# MM32SPINxxxx register map
Vendor: MindMotion Ltd.; Series: MM32SPIN; File version: 1.4
CPU: CM0 r0p0, little endian, no MPU, no FPU, 3 interrupt priority bits
Registers are 32-bit, read-write, reset 0x0 unless marked. A register's access mark holds for its fields unless they carry their own. Offsets are from the block's base; [hi:lo] are bit positions.

## WWDG — Window watchdog
Base 0x40002C00
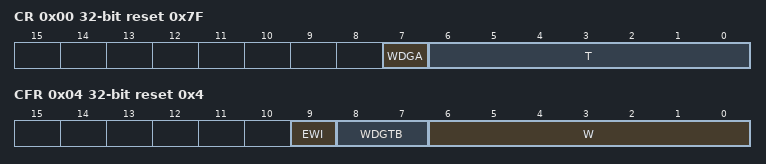
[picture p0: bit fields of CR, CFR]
0x00 CR reset 0x7F
  [7] WDGA — Activation bit
  [6:0] T — 7-bit counter
0x04 CFR reset 0x4
  [9] EWI — Early wakeup interrupt
  [8:7] WDGTB — Timer base
  [6:0] W — 7-bit window value
0x08 SR
  [0] EWIF — Early wakeup interrupt flag

## IWDG — Independent watchdog
Base 0x40003000
0x00 KR wo
  [15:0] KEY — Key value
0x04 PR
  [2:0] PR — Prescaler divider
0x08 RLR
  [11:0] RL — Watchdog counter reload value
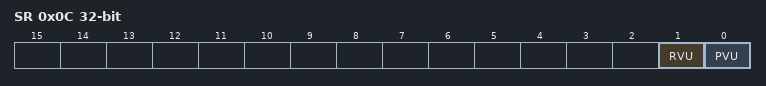
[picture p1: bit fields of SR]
0x0C SR ro
  [1] RVU — Watchdog counter reload value update
  [0] PVU — Watchdog prescaler value update

## TIM14 — Advanced timer
Base 0x40014000
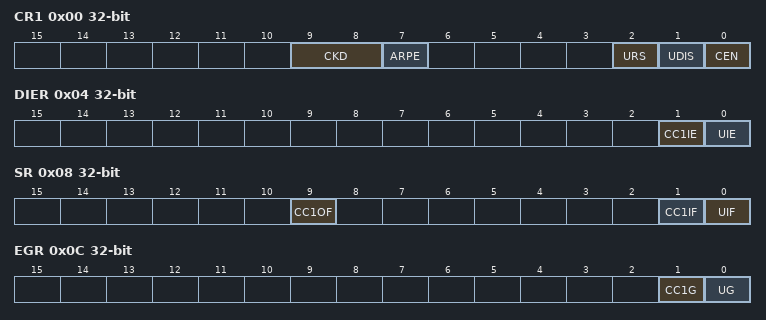
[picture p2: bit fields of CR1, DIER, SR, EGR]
0x00 CR1
  [9:8] CKD, [7] ARPE, [2] URS, [1] UDIS, [0] CEN
0x04 DIER
  [1] CC1IE, [0] UIE
0x08 SR
  [9] CC1OF, [1] CC1IF, [0] UIF
0x0C EGR wo
  [1] CC1G, [0] UG
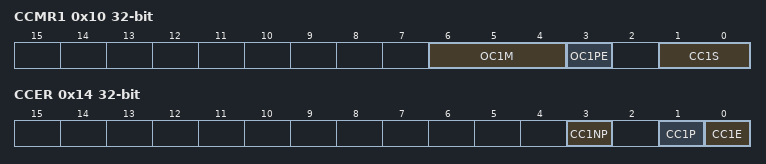
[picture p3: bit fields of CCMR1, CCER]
0x10 CCMR1
  [6:4] OC1M, [3] OC1PE, [1:0] CC1S
0x14 CCER
  [3] CC1NP, [1] CC1P, [0] CC1E
0x18 CNT
  [15:0] CNT
0x1C PSC
  [15:0] PSE
0x20 ARR
  [15:0] ARR
0x24 CRR1
  [15:0] CRR1

## TIM16 — Advanced timer
Base 0x40014400
Same registers: TIM17 0x40014800
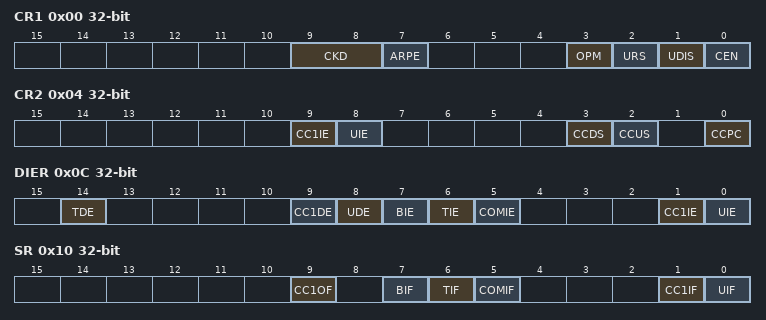
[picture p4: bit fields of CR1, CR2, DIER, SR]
0x00 CR1
  [9:8] CKD, [7] ARPE, [3] OPM, [2] URS, [1] UDIS, [0] CEN
0x04 CR2 — CR3
  [9] CC1IE, [8] UIE, [3] CCDS, [2] CCUS, [0] CCPC
0x0C DIER
  [14] TDE, [9] CC1DE, [8] UDE, [7] BIE, [6] TIE, [5] COMIE, [1] CC1IE, [0] UIE
0x10 SR
  [9] CC1OF, [7] BIF, [6] TIF, [5] COMIF, [1] CC1IF, [0] UIF
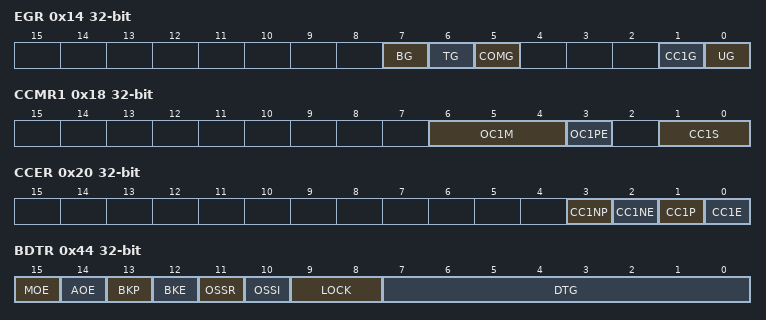
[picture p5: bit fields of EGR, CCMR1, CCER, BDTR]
0x14 EGR wo
  [7] BG, [6] TG, [5] COMG, [1] CC1G, [0] UG
0x18 CCMR1 — CCMR2
  [6:4] OC1M, [3] OC1PE, [1:0] CC1S
0x20 CCER
  [3] CC1NP, [2] CC1NE, [1] CC1P, [0] CC1E
0x24 CNT
  [15:0] CNT
0x28 PSC
  [15:0] PSC
0x2C ARR
  [15:0] ARR
0x30 RCR
  [7:0] REP
0x34 CCR1 — CCR2
  [15:0] CCR1
0x44 BDTR
  [15] MOE, [14] AOE, [13] BKP, [12] BKE, [11] OSSR, [10] OSSI, [9:8] LOCK, [7:0] DTG
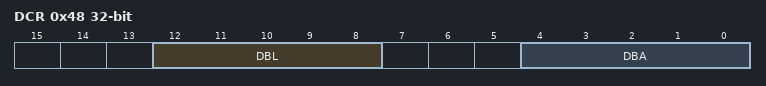
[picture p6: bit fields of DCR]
0x48 DCR
  [12:8] DBL, [4:0] DBA
0x4C DMAR
  [15:0] DMAB

## SPI1 — Serial peripheral interface
Base 0x40013000
Same registers: SPI2 0x40003800
0x00 TXREG
  [31:0] TXREG — Transmit data register
0x04 RXREG ro
  [31:0] RXREG — Receive data register
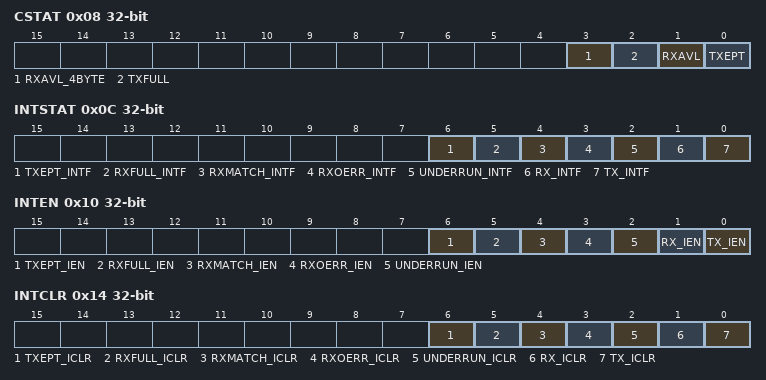
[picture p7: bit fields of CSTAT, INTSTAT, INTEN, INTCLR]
0x08 CSTAT ro
  [3] RXAVL_4BYTE — Receive available 4 byte data message
  [2] TXFULL — Transmitter FIFO full status bit
  [1] RXAVL — Receive available byte data message
  [0] TXEPT — Transmitter empty bit
0x0C INTSTAT
  [6] TXEPT_INTF — Transmitter empty interrupt flag bit
  [5] RXFULL_INTF — RX FIFO full interrupt flag bit
  [4] RXMATCH_INTF — Receive data match the RXDNR number
  [3] RXOERR_INTF — Receive overrun error interrupt flag bit
  [2] UNDERRUN_INTF — SPI underrun interrupt flag bit
  [1] RX_INTF — Receive data available interrupt flag bit
  [0] TX_INTF — Transmit FIFO avialable interrupt flag bit
0x10 INTEN
  [6] TXEPT_IEN — Transmit empty interrupt enable bit
  [5] RXFULL_IEN — Receive FIFO full interrupt enable bit
  [4] RXMATCH_IEN — Receive data complete interrupt enable bit
  [3] RXOERR_IEN — Overrun error interrupt enable bit
  [2] UNDERRUN_IEN — Transmitter underrun interrupt enable bit(SPI slave mode only)
  [1] RX_IEN — Receive FIFO interrupt enable bit
  [0] TX_IEN — Transmit FIFO empty interrupt enable bit
0x14 INTCLR
  [6] TXEPT_ICLR — Transmitter empty interrupt clear bit
  [5] RXFULL_ICLR — Receiver buffer full interrupt clear bit
  [4] RXMATCH_ICLR — Receive completed interrupt clear bit
  [3] RXOERR_ICLR — Overrun error interrupt clear bit
  [2] UNDERRUN_ICLR — Transmitter underrun interrupt clear bit(SPI slave mode only)
  [1] RX_ICLR — Receive interrupt clear bit
  [0] TX_ICLR — Transmitter FIFO empty interrupt clear bit
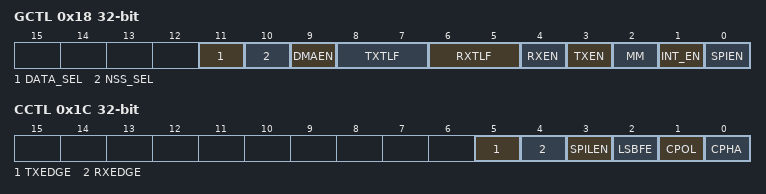
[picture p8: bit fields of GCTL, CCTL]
0x18 GCTL
  [11] DATA_SEL — Valid byte or double-word data select signal
  [10] NSS_SEL — NSS select signal that from software and hardware
  [9] DMAEN — DMA access mode enable
  [8:7] TXTLF — TX FIFO trigger level bit
  [6:5] RXTLF — RX FIFO trigger level bit
  [4] RXEN — Receive enable bit
  [3] TXEN — Transmit enable bit
  [2] MM — Master mode bit
  [1] INT_EN — SPI interrupt enable bit
  [0] SPIEN — SPI select bit
0x1C CCTL
  [5] TXEDGE — Transmit data edge select
  [4] RXEDGE — Receive data edge select
  [3] SPILEN — SPI character length bit
  [2] LSBFE — LSI first enable bit
  [1] CPOL — Clock polarity select bit
  [0] CPHA — Clock phase select bit
0x20 SPBRG
  [31:0] SPBRG — SPI baud rate control register for baud rate
0x24 RXDNR
  [31:0] RXDNR — The register is used to hold a count of to be received bytes in next receive process
0x28 NSSR
  [0] NSS — Chip select output signal in Master mode
0x2C EXTCTL
  [4:0] EXTCTL — 1-32 BIT LENGTH
